VERSION "HIPBYYYYYYYYYYYYYYYYYYYYYYYYYYYYNNNNNNNNNN/4/%%%/4/'%**4NNN///"

NS_ :

BS_:

BU_: ADMM_33970 CSM_GmbH

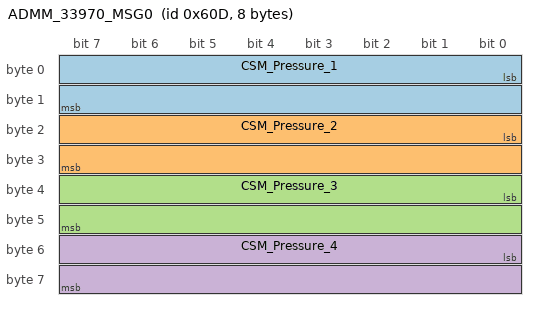
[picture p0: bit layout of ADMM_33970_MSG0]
BO_ 1549 ADMM_33970_MSG0: 8 ADMM_33970
 SG_ CSM_Pressure_1 : 0|16@1- (0.0190740684,-31.25) [0|250] "bar" CSM_GmbH
 SG_ CSM_Pressure_2 : 16|16@1- (0.0190740684,-31.25) [0|250] "bar" CSM_GmbH
 SG_ CSM_Pressure_3 : 32|16@1- (0.0190740684,-31.25) [0|250] "bar" CSM_GmbH
 SG_ CSM_Pressure_4 : 48|16@1- (0.0190740684,-31.25) [0|250] "bar" CSM_GmbH

BA_DEF_  "BusType" STRING ;
BA_DEF_  "CSMconfigVersion" STRING ;
BA_DEF_  "CSMformatVersion" INT 0 255 ;
BA_DEF_ BO_ "GenMsgCycleTime" INT 0 0 ;
BA_DEF_ BO_ "GenMsgSendType" ENUM "Cyclic","not_used","not_used","not_used","not_used","Cyclic","not_used","IfActive","NoMsgSendType";
BA_DEF_ BO_ "CSMcycleTime" INT 0 0 ;
BA_DEF_ BU_ "CSMdeviceType" INT -1 3020 ;
BA_DEF_ BU_ "CSMdeviceDeviceType" INT -1 3020 ;
BA_DEF_ BU_ "CSMdeviceSerialNo" HEX 0 4294967295 ;
BA_DEF_ BU_ "CSMdeviceHash" HEX 0 0 ;
BA_DEF_ BU_ "CSMdeviceChannels" INT 0 16 ;
BA_DEF_  "CSMdata0000" STRING ;
BA_DEF_  "CSMdata0001" STRING ;
BA_DEF_  "CSMdata0002" STRING ;
BA_DEF_  "CSMdata0003" STRING ;
BA_DEF_  "CSMdata0004" STRING ;
BA_DEF_  "CSMdata0005" STRING ;
BA_DEF_  "CSMdata0006" STRING ;
BA_DEF_  "CSMdata0007" STRING ;
BA_DEF_  "CSMdata0008" STRING ;

BA_DEF_DEF_ "BusType" "";
BA_DEF_DEF_ "CSMconfigVersion" "";
BA_DEF_DEF_ "CSMformatVersion" 0 ;
BA_DEF_DEF_ "GenMsgCycleTime" 0 ;
BA_DEF_DEF_ "GenMsgSendType" "NoMsgSendType";
BA_DEF_DEF_ "CSMcycleTime" 0 ;
BA_DEF_DEF_ "CSMdeviceType" -1 ;
BA_DEF_DEF_ "CSMdeviceDeviceType" -1 ;
BA_DEF_DEF_ "CSMdeviceSerialNo" 0 ;
BA_DEF_DEF_ "CSMdeviceHash" 0 ;
BA_DEF_DEF_ "CSMdeviceChannels" 0 ;
BA_DEF_DEF_ "CSMdata0000" "";
BA_DEF_DEF_ "CSMdata0001" "";
BA_DEF_DEF_ "CSMdata0002" "";
BA_DEF_DEF_ "CSMdata0003" "";
BA_DEF_DEF_ "CSMdata0004" "";
BA_DEF_DEF_ "CSMdata0005" "";
BA_DEF_DEF_ "CSMdata0006" "";
BA_DEF_DEF_ "CSMdata0007" "";
BA_DEF_DEF_ "CSMdata0008" "";

BA_ "GenMsgCycleTime" BO_ 1549 10 ;
BA_ "GenMsgSendType" BO_ 1549 0;
BA_ "CSMcycleTime" BO_ 1549 10000 ;
BA_ "BusType"  "CAN";
BA_ "CSMconfigVersion"  "9.10.0.18041";
BA_ "CSMformatVersion"  3 ;
BA_ "CSMdeviceType" BU_ ADMM_33970 4 ;
BA_ "CSMdeviceDeviceType" BU_ ADMM_33970 11 ;
BA_ "CSMdeviceSerialNo" BU_ ADMM_33970 33970 ;
BA_ "CSMdeviceHash" BU_ ADMM_33970 2561666049 ;
BA_ "CSMdeviceChannels" BU_ ADMM_33970 4 ;
BA_ "CSMdata0000"  "6A030000010A000033860D3378DAED564D8FDB3610EDB940FFC354A7068925EAC3B26CAC374813042DBABB5854DBA2B7052D8D2C0212A992B465FFFB0E297F2441D04390E3FA600D87C3C7376F662CDFBC3DF41DEC511BA1E43A884316BCBDFDE9C79BF7";
BA_ "CSMdata0001"  "E57DA56423B6303D2E11CB3066210BE3826571008DD23DB797CD24008293667530621DB4D60EAB281AC7311CD350E96D94301647FFDCDF95558B3D9F09692C9715D2292356C63BEF54C5AD07FBE47865FAB0C6E84AEA6285075307B7373FCF66500A82BA";
BA_ "CSMdata0002"  "EEC006891DC2DF45B80C19545C4A65A1E5B2EE10880348DEA3197885E60DC06C3681D85618A855B5EB515A20BBD2C82DD6300ADBAA9D057E3D0766C04A3462221C5E303E2A0D7BDE899AFC72FB06860EB941E0754DF0489A759D1A69073436A8D1B1B6CA";
BA_ "CSMdata0003"  "6F694514B14377F9150F2651FF5791E012FDD44EE94D1A432328DD5F3ED3EB95CBAB733A535E42FA9B7D29BACE6702B5D05859A58FA09A4FA4F657BC7FF7B0D9191016FBA6E35B629506B01156131AF50FF31F6A0C4D2AD9E3E07CD42786F7A4C2A084B4";
BA_ "CSMdata0004"  "EB20CF031035558B44A2ED007A6E2C6A51AF836C315F26499692F38E9CBF4BF23724F53AF8634F1AEA15FC55FE4AA5843BB16D2D2487DF4A4A8E8A2AB103F60ACAE86195C48BA2A09EF8807B41C53D1B5F50AE713FD1CBBCBDE75A7047CEB3452D1545A5";
BA_ "CSMdata0005"  "CB05F3BB6E15933909D172D352AFCFF338CF73962D03185057138929621D3022F04012DCBEFB707FFFEC916E22EF38D179D46A3060241EE8D2998B0AA01D35EE1D856596E7052BDC808D345CE42A62E25CF1816F4427AC404A224EB2224F17C1D4864ECA";
BA_ "CSMdata0006"  "24A50124409435D60DF5ED4EFBC03C2DE641E46B67D0BAA634DF54B20D958036E72E655153CD0697E867B5A45B9E3497A61716CEF8D41F478B4AD72E13172F1BD51B2F12504D8693ED084E229A8BF545D1AA76E27751979AF3F991923494E9737C56B844";
BA_ "CSMdata0007"  "69CADD307447D8ABCEF22D1D79ED15282B9A4BB97D1AD5A34B0C0E8C765838A75FA098ACCC5947EFA3A7F32473A70C77D3E02359BC648B8CE545466DBA2C928CDA47350DC94A554CE33021809D14B4DA704DBD23CCD0F1632FE484795EF3C3099B38FDC9";
BA_ "CSMdata0008"  "E59646DF7D93D3C9E5ED8D18D4341E7E3981FA031F454763E1269B1E67414ECB46E3BFA7B0E8A4E1B78999BC88F9FDC44C5FC4FC7E62662F627E5DCCE8FAF3194D2F998BE15CD39BDB19E7373AFDD1FBE13FF93C219E";
